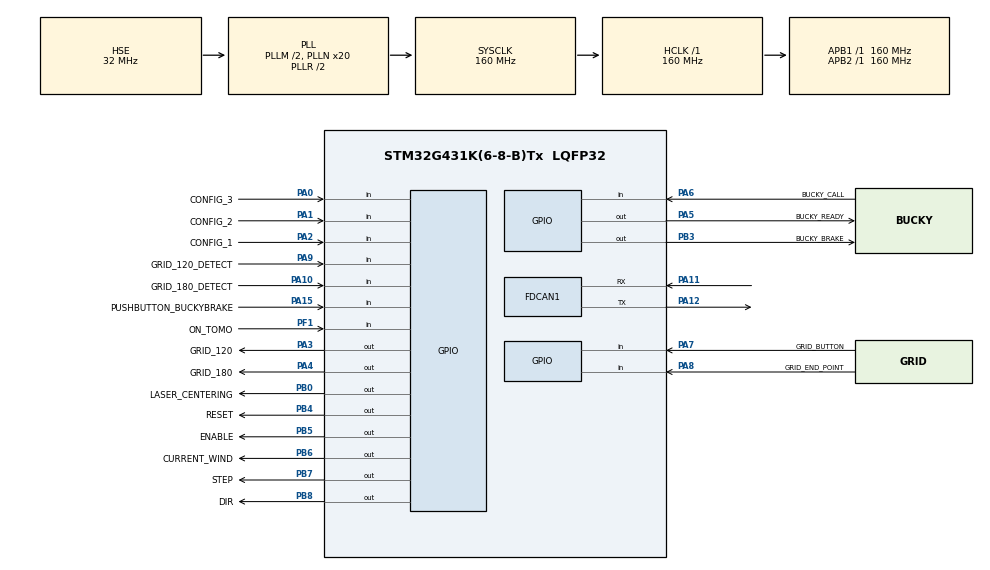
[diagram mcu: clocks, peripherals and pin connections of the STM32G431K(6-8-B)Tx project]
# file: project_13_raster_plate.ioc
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FDCAN1.CalculateBaudRateNominal=2000000
FDCAN1.CalculateTimeBitNominal=500
FDCAN1.CalculateTimeQuantumNominal=100.0
Mcu.Family=STM32G4
Mcu.Name=STM32G431K(6-8-B)Tx
Mcu.Package=LQFP32
NVIC.PriorityGroup=NVIC_PRIORITYGROUP_4
NVIC.TIM2_IRQn=true\:1\:0\:true\:false\:true\:true\:true\:true
NVIC.TIM3_IRQn=true\:2\:0\:true\:false\:true\:true\:true\:true
PA0.GPIO_Label=CONFIG_3
PA0.Signal=GPIO_Input
PA1.GPIO_Label=CONFIG_2
PA1.Signal=GPIO_Input
PA10.GPIO_Label=GRID_180_DETECT
PA10.Signal=GPIO_Input
PA11.Mode=FDCAN_Activate
PA11.Signal=FDCAN1_RX
PA12.Mode=FDCAN_Activate
PA12.Signal=FDCAN1_TX
PA13.Mode=Serial_Wire
PA13.Signal=SYS_JTMS-SWDIO
PA14.Mode=Serial_Wire
PA14.Signal=SYS_JTCK-SWCLK
PA15.GPIO_Label=PUSHBUTTON_BUCKYBRAKE
PA15.Signal=GPIO_Input
PA2.GPIO_Label=CONFIG_1
PA2.Signal=GPIO_Input
PA3.GPIO_Label=GRID_120
PA3.Signal=GPIO_Output
PA4.GPIO_Label=GRID_180
PA4.Signal=GPIO_Output
PA5.GPIO_Label=BUCKY_READY
PA5.Signal=GPIO_Output
PA6.GPIO_Label=BUCKY_CALL
PA6.Signal=GPIO_Input
PA7.GPIO_Label=GRID_BUTTON
PA7.Signal=GPIO_Input
PA8.GPIO_Label=GRID_END_POINT
PA8.Signal=GPIO_Input
PA9.GPIO_Label=GRID_120_DETECT
PA9.Signal=GPIO_Input
PB0.GPIO_Label=LASER_CENTERING
PB0.Signal=GPIO_Output
PB3.GPIO_Label=BUCKY_BRAKE
PB3.Signal=GPIO_Output
PB4.GPIO_Label=RESET
PB4.Signal=GPIO_Output
PB5.GPIO_Label=ENABLE
PB5.Signal=GPIO_Output
PB6.GPIO_Label=CURRENT_WIND
PB6.Signal=GPIO_Output
PB7.GPIO_Label=STEP
PB7.Signal=GPIO_Output
PB8-BOOT0.GPIO_Label=DIR
PB8-BOOT0.Signal=GPIO_Output
PF0-OSC_IN.Mode=HSE-External-Clock-Source
PF0-OSC_IN.Signal=RCC_OSC_IN
PF1-OSC_OUT.GPIO_Label=ON_TOMO
PF1-OSC_OUT.Signal=GPIO_Input
ProjectManager.HeapSize=0x200
ProjectManager.StackSize=0x400
ProjectManager.TargetToolchain=STM32CubeIDE
RCC.ADC12Freq_Value=160000000
RCC.AHBFreq_Value=160000000
RCC.APB1Freq_Value=160000000
RCC.APB1TimFreq_Value=160000000
RCC.APB2Freq_Value=160000000
RCC.APB2TimFreq_Value=160000000
RCC.CortexFreq_Value=160000000
RCC.EXTERNAL_CLOCK_VALUE=12288000
RCC.HCLKFreq_Value=160000000
RCC.HSE_VALUE=32000000
RCC.HSI48_VALUE=48000000
RCC.HSI_VALUE=16000000
RCC.LSE_VALUE=32768
RCC.PLLM=RCC_PLLM_DIV2
RCC.PLLN=20
RCC.PLLSourceVirtual=RCC_PLLSOURCE_HSE
RCC.SYSCLKFreq_VALUE=160000000
RCC.SYSCLKSource=RCC_SYSCLKSOURCE_PLLCLK
RCC.USBFreq_Value=160000000
RCC.VCOOutputFreq_Value=320000000
TIM2.PeriodNoDither=99999
TIM2.Prescaler=159
TIM2.TIM_MasterOutputTrigger=TIM_TRGO_UPDATE
TIM3.CounterMode=TIM_COUNTERMODE_DOWN
TIM3.PeriodNoDither=99
TIM3.Prescaler=7
TIM3.TIM_MasterOutputTrigger=TIM_TRGO_UPDATE
VP_SYS_VS_DBSignals.Mode=DisableDeadBatterySignals
VP_TIM2_VS_ClockSourceINT.Mode=Internal
VP_TIM3_VS_ClockSourceINT.Mode=Internal
board=custom

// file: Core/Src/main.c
/* USER CODE BEGIN Header */
/**
  ******************************************************************************
  * @file           : main.c
  * @brief          : Main program body
  ******************************************************************************
  * @attention
  *
  * <h2><center>&copy; Copyright (c) 2020 STMicroelectronics.
  * All rights reserved.</center></h2>
  *
  * This software component is licensed by ST under BSD 3-Clause license,
  * the "License"; You may not use this file except in compliance with the
  * License. You may obtain a copy of the License at:
  *                        opensource.org/licenses/BSD-3-Clause
  *
  ******************************************************************************
  */
/* USER CODE END Header */
#include "main.h"

FDCAN_HandleTypeDef hfdcan1;

TIM_HandleTypeDef htim2;
TIM_HandleTypeDef htim3;

void SystemClock_Config(void);
static void MX_GPIO_Init(void);
static void MX_TIM2_Init(void);
static void MX_TIM3_Init(void);
static void MX_FDCAN1_Init(void);

int main(void)
{

  /* MCU Configuration--------------------------------------------------------*/

  /* Reset of all peripherals, Initializes the Flash interface and the Systick. */
  HAL_Init();

  /* Configure the system clock */
  SystemClock_Config();

  /* Initialize all configured peripherals */
  MX_GPIO_Init();
  MX_TIM2_Init();
  MX_TIM3_Init();
  MX_FDCAN1_Init();
  /* USER CODE BEGIN 2 */
  device_init();
  /* USER CODE END 2 */

  /* Infinite loop */
  while (1)
  {

  }
}

void SystemClock_Config(void)
{
  RCC_OscInitTypeDef RCC_OscInitStruct = {0};
  RCC_ClkInitTypeDef RCC_ClkInitStruct = {0};

  /** Configure the main internal regulator output voltage
  */
  HAL_PWREx_ControlVoltageScaling(PWR_REGULATOR_VOLTAGE_SCALE1_BOOST);

  /** Initializes the RCC Oscillators according to the specified parameters
  * in the RCC_OscInitTypeDef structure.
  */
  RCC_OscInitStruct.OscillatorType = RCC_OSCILLATORTYPE_HSE;
  RCC_OscInitStruct.HSEState = RCC_HSE_BYPASS;
  RCC_OscInitStruct.PLL.PLLState = RCC_PLL_ON;
  RCC_OscInitStruct.PLL.PLLSource = RCC_PLLSOURCE_HSE;
  RCC_OscInitStruct.PLL.PLLM = RCC_PLLM_DIV2;
  RCC_OscInitStruct.PLL.PLLN = 20;
  RCC_OscInitStruct.PLL.PLLP = RCC_PLLP_DIV2;
  RCC_OscInitStruct.PLL.PLLQ = RCC_PLLQ_DIV2;
  RCC_OscInitStruct.PLL.PLLR = RCC_PLLR_DIV2;
  if (HAL_RCC_OscConfig(&RCC_OscInitStruct) != HAL_OK)
  {
    Error_Handler();
  }

  /** Initializes the CPU, AHB and APB buses clocks
  */
  RCC_ClkInitStruct.ClockType = RCC_CLOCKTYPE_HCLK|RCC_CLOCKTYPE_SYSCLK
                              |RCC_CLOCKTYPE_PCLK1|RCC_CLOCKTYPE_PCLK2;
  RCC_ClkInitStruct.SYSCLKSource = RCC_SYSCLKSOURCE_PLLCLK;
  RCC_ClkInitStruct.AHBCLKDivider = RCC_SYSCLK_DIV1;
  RCC_ClkInitStruct.APB1CLKDivider = RCC_HCLK_DIV1;
  RCC_ClkInitStruct.APB2CLKDivider = RCC_HCLK_DIV1;

  if (HAL_RCC_ClockConfig(&RCC_ClkInitStruct, FLASH_LATENCY_4) != HAL_OK)
  {
    Error_Handler();
  }
}

static void MX_FDCAN1_Init(void)
{

  hfdcan1.Instance = FDCAN1;
  hfdcan1.Init.ClockDivider = FDCAN_CLOCK_DIV1;
  hfdcan1.Init.FrameFormat = FDCAN_FRAME_CLASSIC;
  hfdcan1.Init.Mode = FDCAN_MODE_NORMAL;
  hfdcan1.Init.AutoRetransmission = DISABLE;
  hfdcan1.Init.TransmitPause = DISABLE;
  hfdcan1.Init.ProtocolException = DISABLE;
  hfdcan1.Init.NominalPrescaler = 16;
  hfdcan1.Init.NominalSyncJumpWidth = 1;
  hfdcan1.Init.NominalTimeSeg1 = 2;
  hfdcan1.Init.NominalTimeSeg2 = 2;
  hfdcan1.Init.DataPrescaler = 1;
  hfdcan1.Init.DataSyncJumpWidth = 1;
  hfdcan1.Init.DataTimeSeg1 = 1;
  hfdcan1.Init.DataTimeSeg2 = 1;
  hfdcan1.Init.StdFiltersNbr = 0;
  hfdcan1.Init.ExtFiltersNbr = 0;
  hfdcan1.Init.TxFifoQueueMode = FDCAN_TX_FIFO_OPERATION;
  if (HAL_FDCAN_Init(&hfdcan1) != HAL_OK)
  {
    Error_Handler();
  }

}

static void MX_TIM2_Init(void)
{

  TIM_ClockConfigTypeDef sClockSourceConfig = {0};
  TIM_MasterConfigTypeDef sMasterConfig = {0};

  htim2.Instance = TIM2;
  htim2.Init.Prescaler = 159;
  htim2.Init.CounterMode = TIM_COUNTERMODE_UP;
  htim2.Init.Period = 99999;
  htim2.Init.ClockDivision = TIM_CLOCKDIVISION_DIV1;
  htim2.Init.AutoReloadPreload = TIM_AUTORELOAD_PRELOAD_DISABLE;
  if (HAL_TIM_Base_Init(&htim2) != HAL_OK)
  {
    Error_Handler();
  }
  sClockSourceConfig.ClockSource = TIM_CLOCKSOURCE_INTERNAL;
  if (HAL_TIM_ConfigClockSource(&htim2, &sClockSourceConfig) != HAL_OK)
  {
    Error_Handler();
  }
  sMasterConfig.MasterOutputTrigger = TIM_TRGO_UPDATE;
  sMasterConfig.MasterSlaveMode = TIM_MASTERSLAVEMODE_DISABLE;
  if (HAL_TIMEx_MasterConfigSynchronization(&htim2, &sMasterConfig) != HAL_OK)
  {
    Error_Handler();
  }

}

static void MX_TIM3_Init(void)
{

  TIM_ClockConfigTypeDef sClockSourceConfig = {0};
  TIM_MasterConfigTypeDef sMasterConfig = {0};

  htim3.Instance = TIM3;
  htim3.Init.Prescaler = 7;
  htim3.Init.CounterMode = TIM_COUNTERMODE_DOWN;
  htim3.Init.Period = 99;
  htim3.Init.ClockDivision = TIM_CLOCKDIVISION_DIV1;
  htim3.Init.AutoReloadPreload = TIM_AUTORELOAD_PRELOAD_DISABLE;
  if (HAL_TIM_Base_Init(&htim3) != HAL_OK)
  {
    Error_Handler();
  }
  sClockSourceConfig.ClockSource = TIM_CLOCKSOURCE_INTERNAL;
  if (HAL_TIM_ConfigClockSource(&htim3, &sClockSourceConfig) != HAL_OK)
  {
    Error_Handler();
  }
  sMasterConfig.MasterOutputTrigger = TIM_TRGO_UPDATE;
  sMasterConfig.MasterSlaveMode = TIM_MASTERSLAVEMODE_DISABLE;
  if (HAL_TIMEx_MasterConfigSynchronization(&htim3, &sMasterConfig) != HAL_OK)
  {
    Error_Handler();
  }

}

static void MX_GPIO_Init(void)
{
  GPIO_InitTypeDef GPIO_InitStruct = {0};

  /* GPIO Ports Clock Enable */
  __HAL_RCC_GPIOF_CLK_ENABLE();
  __HAL_RCC_GPIOA_CLK_ENABLE();
  __HAL_RCC_GPIOB_CLK_ENABLE();

  /*Configure GPIO pin Output Level */
  HAL_GPIO_WritePin(GPIOA, GRID_120_Pin|GRID_180_Pin|BUCKY_READY_Pin, GPIO_PIN_RESET);

  /*Configure GPIO pin Output Level */
  HAL_GPIO_WritePin(GPIOB, LASER_CENTERING_Pin|BUCKY_BRAKE_Pin|RESET_Pin|ENABLE_Pin
                          |CURRENT_WIND_Pin|STEP_Pin|DIR_Pin, GPIO_PIN_RESET);

  /*Configure GPIO pin : ON_TOMO_Pin */
  GPIO_InitStruct.Pin = ON_TOMO_Pin;
  GPIO_InitStruct.Mode = GPIO_MODE_INPUT;
  GPIO_InitStruct.Pull = GPIO_NOPULL;
  HAL_GPIO_Init(ON_TOMO_GPIO_Port, &GPIO_InitStruct);

  /*Configure GPIO pins : CONFIG_3_Pin CONFIG_2_Pin CONFIG_1_Pin BUCKY_CALL_Pin
                           GRID_BUTTON_Pin GRID_END_POINT_Pin GRID_120_DETECT_Pin GRID_180_DETECT_Pin
                           PUSHBUTTON_BUCKYBRAKE_Pin */
  GPIO_InitStruct.Pin = CONFIG_3_Pin|CONFIG_2_Pin|CONFIG_1_Pin|BUCKY_CALL_Pin
                          |GRID_BUTTON_Pin|GRID_END_POINT_Pin|GRID_120_DETECT_Pin|GRID_180_DETECT_Pin
                          |PUSHBUTTON_BUCKYBRAKE_Pin;
  GPIO_InitStruct.Mode = GPIO_MODE_INPUT;
  GPIO_InitStruct.Pull = GPIO_NOPULL;
  HAL_GPIO_Init(GPIOA, &GPIO_InitStruct);

  /*Configure GPIO pins : GRID_120_Pin GRID_180_Pin BUCKY_READY_Pin */
  GPIO_InitStruct.Pin = GRID_120_Pin|GRID_180_Pin|BUCKY_READY_Pin;
  GPIO_InitStruct.Mode = GPIO_MODE_OUTPUT_PP;
  GPIO_InitStruct.Pull = GPIO_NOPULL;
  GPIO_InitStruct.Speed = GPIO_SPEED_FREQ_LOW;
  HAL_GPIO_Init(GPIOA, &GPIO_InitStruct);

  /*Configure GPIO pins : LASER_CENTERING_Pin BUCKY_BRAKE_Pin RESET_Pin ENABLE_Pin
                           CURRENT_WIND_Pin STEP_Pin DIR_Pin */
  GPIO_InitStruct.Pin = LASER_CENTERING_Pin|BUCKY_BRAKE_Pin|RESET_Pin|ENABLE_Pin
                          |CURRENT_WIND_Pin|STEP_Pin|DIR_Pin;
  GPIO_InitStruct.Mode = GPIO_MODE_OUTPUT_PP;
  GPIO_InitStruct.Pull = GPIO_NOPULL;
  GPIO_InitStruct.Speed = GPIO_SPEED_FREQ_LOW;
  HAL_GPIO_Init(GPIOB, &GPIO_InitStruct);

}

void Error_Handler(void)
{
}
